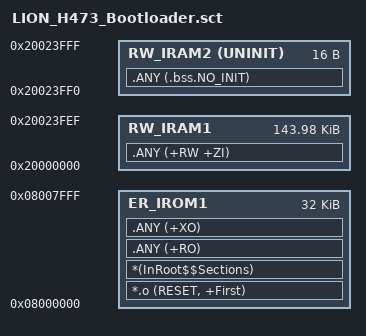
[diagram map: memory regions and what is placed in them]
; *************************************************************
; *** Scatter-Loading Description File generated by uVision ***
; *************************************************************

; 前 32 KB (0x08000000..0x08007FFF) 是 bootloader，App 链接在 0x08008000。
; 这里把 load/exec 区限死在 32 KB：bootloader 长大后链接直接报错，而不会悄悄
; 覆盖 App（App 侧的 N32H473CE_FLASH.ld / ODrive_N32.sct 已收紧到 0x08008000）。
LR_IROM1 0x08000000 0x00008000  {    ; load region size_region
  ER_IROM1 0x08000000 0x00008000  {  ; load address = execution address
   *.o (RESET, +First)
   *(InRoot$$Sections)
   .ANY (+RO)
   .ANY (+XO)
  }
  RW_IRAM1 0x20000000 0x00023FF0  {  ; RW data (144KB - 16B)
   .ANY (+RW +ZI)
  }
  ; UNINIT: never zeroed by startup, value survives NVIC_SystemReset().
  ; Shared with APP's _reboot_cookie at this same address (ODrive_N32.sct RW_IRAM2).
  ; Bootloader accesses this via BOOT_MAGIC_ADDR pointer in main.c.
  RW_IRAM2 0x20023FF0 UNINIT 0x00000010  {
   .ANY (.bss.NO_INIT)
  }
}

